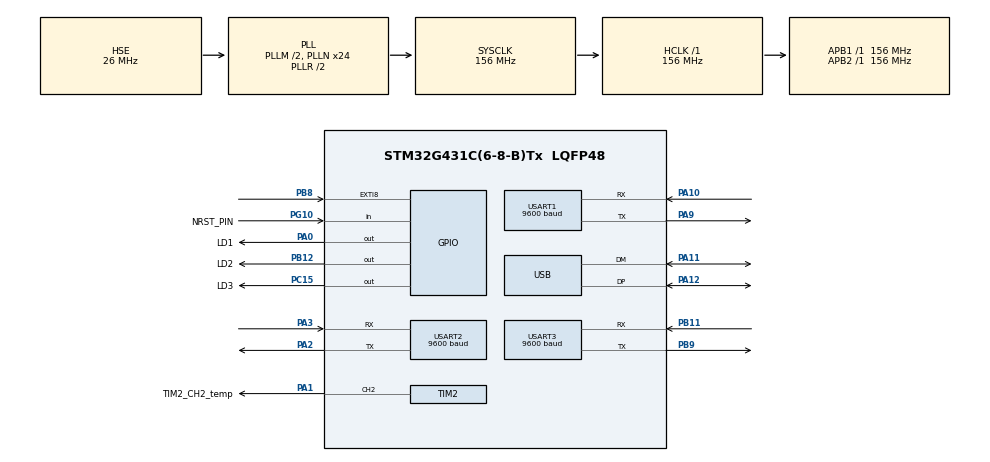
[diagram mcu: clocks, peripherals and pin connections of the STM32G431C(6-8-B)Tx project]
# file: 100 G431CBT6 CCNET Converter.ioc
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Dma.Request0=USART2_TX
Dma.Request1=USART1_TX
Dma.Request2=USART3_TX
Dma.USART1_TX.1.Direction=DMA_MEMORY_TO_PERIPH
Dma.USART1_TX.1.EventEnable=DISABLE
Dma.USART1_TX.1.Instance=DMA1_Channel2
Dma.USART1_TX.1.MemDataAlignment=DMA_MDATAALIGN_BYTE
Dma.USART1_TX.1.MemInc=DMA_MINC_ENABLE
Dma.USART1_TX.1.Mode=DMA_NORMAL
Dma.USART1_TX.1.PeriphDataAlignment=DMA_PDATAALIGN_BYTE
Dma.USART1_TX.1.PeriphInc=DMA_PINC_DISABLE
Dma.USART1_TX.1.Polarity=HAL_DMAMUX_REQ_GEN_RISING
Dma.USART1_TX.1.Priority=DMA_PRIORITY_MEDIUM
Dma.USART1_TX.1.RequestNumber=1
Dma.USART1_TX.1.SignalID=NONE
Dma.USART1_TX.1.SyncEnable=DISABLE
Dma.USART1_TX.1.SyncPolarity=HAL_DMAMUX_SYNC_NO_EVENT
Dma.USART1_TX.1.SyncRequestNumber=1
Dma.USART1_TX.1.SyncSignalID=NONE
Dma.USART2_TX.0.Direction=DMA_MEMORY_TO_PERIPH
Dma.USART2_TX.0.EventEnable=DISABLE
Dma.USART2_TX.0.Instance=DMA1_Channel1
Dma.USART2_TX.0.MemDataAlignment=DMA_MDATAALIGN_BYTE
Dma.USART2_TX.0.MemInc=DMA_MINC_ENABLE
Dma.USART2_TX.0.Mode=DMA_NORMAL
Dma.USART2_TX.0.PeriphDataAlignment=DMA_PDATAALIGN_BYTE
Dma.USART2_TX.0.PeriphInc=DMA_PINC_DISABLE
Dma.USART2_TX.0.Polarity=HAL_DMAMUX_REQ_GEN_RISING
Dma.USART2_TX.0.Priority=DMA_PRIORITY_MEDIUM
Dma.USART2_TX.0.RequestNumber=1
Dma.USART2_TX.0.SignalID=NONE
Dma.USART2_TX.0.SyncEnable=DISABLE
Dma.USART2_TX.0.SyncPolarity=HAL_DMAMUX_SYNC_NO_EVENT
Dma.USART2_TX.0.SyncRequestNumber=1
Dma.USART2_TX.0.SyncSignalID=NONE
Dma.USART3_TX.2.Direction=DMA_MEMORY_TO_PERIPH
Dma.USART3_TX.2.EventEnable=DISABLE
Dma.USART3_TX.2.Instance=DMA1_Channel3
Dma.USART3_TX.2.MemDataAlignment=DMA_MDATAALIGN_BYTE
Dma.USART3_TX.2.MemInc=DMA_MINC_ENABLE
Dma.USART3_TX.2.Mode=DMA_NORMAL
Dma.USART3_TX.2.PeriphDataAlignment=DMA_PDATAALIGN_BYTE
Dma.USART3_TX.2.PeriphInc=DMA_PINC_DISABLE
Dma.USART3_TX.2.Polarity=HAL_DMAMUX_REQ_GEN_RISING
Dma.USART3_TX.2.Priority=DMA_PRIORITY_LOW
Dma.USART3_TX.2.RequestNumber=1
Dma.USART3_TX.2.SignalID=NONE
Dma.USART3_TX.2.SyncEnable=DISABLE
Dma.USART3_TX.2.SyncPolarity=HAL_DMAMUX_SYNC_NO_EVENT
Dma.USART3_TX.2.SyncRequestNumber=1
Dma.USART3_TX.2.SyncSignalID=NONE
Mcu.Family=STM32G4
Mcu.Name=STM32G431C(6-8-B)Tx
Mcu.Package=LQFP48
NVIC.DMA1_Channel1_IRQn=true\:0\:0\:false\:false\:true\:false\:true\:true
NVIC.DMA1_Channel2_IRQn=true\:0\:0\:false\:false\:true\:false\:true\:true
NVIC.DMA1_Channel3_IRQn=true\:0\:0\:false\:false\:true\:false\:true\:true
NVIC.EXTI9_5_IRQn=true\:0\:0\:false\:false\:true\:true\:true\:true
NVIC.PriorityGroup=NVIC_PRIORITYGROUP_4
NVIC.TIM1_TRG_COM_TIM17_IRQn=true\:0\:0\:false\:false\:true\:true\:true\:true
NVIC.TIM1_UP_TIM16_IRQn=true\:0\:0\:false\:false\:true\:true\:true\:true
NVIC.USART1_IRQn=true\:0\:0\:false\:false\:true\:true\:true\:true
NVIC.USART2_IRQn=true\:0\:0\:false\:false\:true\:true\:true\:true
NVIC.USART3_IRQn=true\:0\:0\:false\:false\:true\:true\:true\:true
NVIC.USB_LP_IRQn=true\:0\:0\:false\:false\:true\:false\:true\:true
PA0.GPIO_Label=LD1
PA0.Signal=GPIO_Output
PA1.GPIO_Label=TIM2_CH2_temp
PA1.GPIO_Speed=GPIO_SPEED_FREQ_VERY_HIGH
PA1.Signal=S_TIM2_CH2
PA10.Mode=Asynchronous
PA10.Signal=USART1_RX
PA11.Mode=Device
PA11.Signal=USB_DM
PA12.Mode=Device
PA12.Signal=USB_DP
PA13.Mode=Trace_Asynchronous_SW
PA13.Signal=SYS_JTMS-SWDIO
PA14.Mode=Trace_Asynchronous_SW
PA14.Signal=SYS_JTCK-SWCLK
PA2.Mode=Asynchronous
PA2.Signal=USART2_TX
PA3.Mode=Asynchronous
PA3.Signal=USART2_RX
PA9.Mode=Asynchronous
PA9.Signal=USART1_TX
PB11.Mode=Asynchronous
PB11.Signal=USART3_RX
PB12.GPIO_Label=LD2
PB12.Signal=GPIO_Output
PB3.Mode=Trace_Asynchronous_SW
PB3.Signal=SYS_JTDO-SWO
PB8-BOOT0.GPIO_ModeDefaultEXTI=GPIO_MODE_IT_RISING_FALLING
PB8-BOOT0.Signal=GPXTI8
PB9.GPIO_ModeDefaultPP=GPIO_MODE_AF_OD
PB9.Mode=Asynchronous
PB9.Signal=USART3_TX
PC15-OSC32_OUT.GPIO_Label=LD3
PC15-OSC32_OUT.Signal=GPIO_Output
PF0-OSC_IN.Mode=HSE-External-Clock-Source
PF0-OSC_IN.Signal=RCC_OSC_IN
PG10-NRST.GPIO_Label=NRST_PIN
PG10-NRST.Signal=GPIO_Input
ProjectManager.HeapSize=0x200
ProjectManager.StackSize=0x400
ProjectManager.TargetToolchain=STM32CubeIDE
RCC.ADC12Freq_Value=156000000
RCC.AHBFreq_Value=156000000
RCC.APB1Freq_Value=156000000
RCC.APB1TimFreq_Value=156000000
RCC.APB2Freq_Value=156000000
RCC.APB2TimFreq_Value=156000000
RCC.CK48CLockSelection=RCC_USBCLKSOURCE_HSI48
RCC.CortexFreq_Value=156000000
RCC.EXTERNAL_CLOCK_VALUE=12288000
RCC.HCLKFreq_Value=156000000
RCC.HSE_VALUE=26000000
RCC.HSI48_VALUE=48000000
RCC.HSI_VALUE=16000000
RCC.LSE_VALUE=32768
RCC.PLLM=RCC_PLLM_DIV2
RCC.PLLN=24
RCC.PLLQ=RCC_PLLQ_DIV4
RCC.PLLSourceVirtual=RCC_PLLSOURCE_HSE
RCC.SYSCLKFreq_VALUE=156000000
RCC.SYSCLKSource=RCC_SYSCLKSOURCE_PLLCLK
RCC.USBFreq_Value=48000000
RCC.VCOOutputFreq_Value=312000000
SH.S_TIM2_CH2.0=TIM2_CH2,PWM Generation2 CH2
TIM17.Prescaler=15600-1
TIM2.Channel-PWM\ Generation2\ CH2=TIM_CHANNEL_2
TIM2.PeriodNoDither=6-1
TIM2.Prescaler=1-1
TIM2.PulseNoDither_2=3
USART1.BaudRate=9600
USART1.VirtualMode-Asynchronous=VM_ASYNC
USART2.BaudRate=9600
USART2.Parity=PARITY_EVEN
USART2.VirtualMode-Asynchronous=VM_ASYNC
USART2.WordLength=WORDLENGTH_9B
USART3.BaudRate=9600
USART3.TxPinLevelInvertParam=ADVFEATURE_TXINV_DISABLE
USART3.VirtualMode-Asynchronous=VM_ASYNC
USB_DEVICE.CLASS_NAME_FS=CDC
USB_DEVICE.VirtualMode=Cdc
USB_DEVICE.VirtualModeFS=Cdc_FS
VP_SYS_VS_DBSignals.Mode=DisableDeadBatterySignals
VP_TIM16_VS_ClockSourceINT.Mode=Enable_Timer
VP_TIM17_VS_ClockSourceINT.Mode=Enable_Timer
VP_USB_DEVICE_VS_USB_DEVICE_CDC_FS.Mode=CDC_FS
board=custom

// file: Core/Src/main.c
/* USER CODE BEGIN Header */
/**
  ******************************************************************************
  * @file           : main.c
  * @brief          : Main program body
  ******************************************************************************
  * @attention
  *
  * Copyright (c) 2025 STMicroelectronics.
  * All rights reserved.
  *
  * This software is licensed under terms that can be found in the LICENSE file
  * in the root directory of this software component.
  * If no LICENSE file comes with this software, it is provided AS-IS.
  *
  ******************************************************************************
  */
/* USER CODE END Header */
#include "main.h"
#include "usb_device.h"

/* USER CODE BEGIN Includes */
#include "app.h"
/* USER CODE END Includes */

TIM_HandleTypeDef htim2;
TIM_HandleTypeDef htim16;
TIM_HandleTypeDef htim17;

UART_HandleTypeDef huart1;
UART_HandleTypeDef huart2;
UART_HandleTypeDef huart3;
DMA_HandleTypeDef hdma_usart1_tx;
DMA_HandleTypeDef hdma_usart2_tx;
DMA_HandleTypeDef hdma_usart3_tx;

void SystemClock_Config(void);
static void MX_GPIO_Init(void);
static void MX_DMA_Init(void);
static void MX_USART1_UART_Init(void);
static void MX_USART2_UART_Init(void);
static void MX_USART3_UART_Init(void);
static void MX_TIM2_Init(void);
static void MX_TIM17_Init(void);
static void MX_TIM16_Init(void);

int main(void)
{

  /* MCU Configuration--------------------------------------------------------*/

  /* Reset of all peripherals, Initializes the Flash interface and the Systick. */
  HAL_Init();

  /* Configure the system clock */
  SystemClock_Config();

  /* Initialize all configured peripherals */
  MX_GPIO_Init();
  MX_DMA_Init();
  MX_USART1_UART_Init();
  MX_USART2_UART_Init();
  MX_USART3_UART_Init();
  MX_TIM2_Init();
  MX_TIM17_Init();
  MX_USB_Device_Init();
  MX_TIM16_Init();
  /* USER CODE BEGIN 2 */
  /* Initialize application */
  APP_Init();
  /* USER CODE END 2 */

  /* Infinite loop */
  while (1)
  {

    /* USER CODE BEGIN 3 */
    /* Process application */
    APP_Process();
  }
  /* USER CODE END 3 */
}

void SystemClock_Config(void)
{
  RCC_OscInitTypeDef RCC_OscInitStruct = {0};
  RCC_ClkInitTypeDef RCC_ClkInitStruct = {0};

  /** Configure the main internal regulator output voltage
  */
  HAL_PWREx_ControlVoltageScaling(PWR_REGULATOR_VOLTAGE_SCALE1_BOOST);

  /** Initializes the RCC Oscillators according to the specified parameters
  * in the RCC_OscInitTypeDef structure.
  */
  RCC_OscInitStruct.OscillatorType = RCC_OSCILLATORTYPE_HSI48|RCC_OSCILLATORTYPE_HSE;
  RCC_OscInitStruct.HSEState = RCC_HSE_BYPASS;
  RCC_OscInitStruct.HSI48State = RCC_HSI48_ON;
  RCC_OscInitStruct.PLL.PLLState = RCC_PLL_ON;
  RCC_OscInitStruct.PLL.PLLSource = RCC_PLLSOURCE_HSE;
  RCC_OscInitStruct.PLL.PLLM = RCC_PLLM_DIV2;
  RCC_OscInitStruct.PLL.PLLN = 24;
  RCC_OscInitStruct.PLL.PLLP = RCC_PLLP_DIV2;
  RCC_OscInitStruct.PLL.PLLQ = RCC_PLLQ_DIV4;
  RCC_OscInitStruct.PLL.PLLR = RCC_PLLR_DIV2;
  if (HAL_RCC_OscConfig(&RCC_OscInitStruct) != HAL_OK)
  {
    Error_Handler();
  }

  /** Initializes the CPU, AHB and APB buses clocks
  */
  RCC_ClkInitStruct.ClockType = RCC_CLOCKTYPE_HCLK|RCC_CLOCKTYPE_SYSCLK
                              |RCC_CLOCKTYPE_PCLK1|RCC_CLOCKTYPE_PCLK2;
  RCC_ClkInitStruct.SYSCLKSource = RCC_SYSCLKSOURCE_PLLCLK;
  RCC_ClkInitStruct.AHBCLKDivider = RCC_SYSCLK_DIV1;
  RCC_ClkInitStruct.APB1CLKDivider = RCC_HCLK_DIV1;
  RCC_ClkInitStruct.APB2CLKDivider = RCC_HCLK_DIV1;

  if (HAL_RCC_ClockConfig(&RCC_ClkInitStruct, FLASH_LATENCY_4) != HAL_OK)
  {
    Error_Handler();
  }
}

static void MX_TIM2_Init(void)
{

  TIM_MasterConfigTypeDef sMasterConfig = {0};
  TIM_OC_InitTypeDef sConfigOC = {0};

  htim2.Instance = TIM2;
  htim2.Init.Prescaler = 1-1;
  htim2.Init.CounterMode = TIM_COUNTERMODE_UP;
  htim2.Init.Period = 5;
  htim2.Init.ClockDivision = TIM_CLOCKDIVISION_DIV1;
  htim2.Init.AutoReloadPreload = TIM_AUTORELOAD_PRELOAD_DISABLE;
  if (HAL_TIM_PWM_Init(&htim2) != HAL_OK)
  {
    Error_Handler();
  }
  sMasterConfig.MasterOutputTrigger = TIM_TRGO_RESET;
  sMasterConfig.MasterSlaveMode = TIM_MASTERSLAVEMODE_DISABLE;
  if (HAL_TIMEx_MasterConfigSynchronization(&htim2, &sMasterConfig) != HAL_OK)
  {
    Error_Handler();
  }
  sConfigOC.OCMode = TIM_OCMODE_PWM1;
  sConfigOC.Pulse = 3;
  sConfigOC.OCPolarity = TIM_OCPOLARITY_HIGH;
  sConfigOC.OCFastMode = TIM_OCFAST_DISABLE;
  if (HAL_TIM_PWM_ConfigChannel(&htim2, &sConfigOC, TIM_CHANNEL_2) != HAL_OK)
  {
    Error_Handler();
  }
  HAL_TIM_MspPostInit(&htim2);

}

static void MX_TIM16_Init(void)
{

  htim16.Instance = TIM16;
  htim16.Init.Prescaler = 0;
  htim16.Init.CounterMode = TIM_COUNTERMODE_UP;
  htim16.Init.Period = 65535;
  htim16.Init.ClockDivision = TIM_CLOCKDIVISION_DIV1;
  htim16.Init.RepetitionCounter = 0;
  htim16.Init.AutoReloadPreload = TIM_AUTORELOAD_PRELOAD_DISABLE;
  if (HAL_TIM_Base_Init(&htim16) != HAL_OK)
  {
    Error_Handler();
  }

}

static void MX_TIM17_Init(void)
{

  htim17.Instance = TIM17;
  htim17.Init.Prescaler = 15600-1;
  htim17.Init.CounterMode = TIM_COUNTERMODE_UP;
  htim17.Init.Period = 65535;
  htim17.Init.ClockDivision = TIM_CLOCKDIVISION_DIV1;
  htim17.Init.RepetitionCounter = 0;
  htim17.Init.AutoReloadPreload = TIM_AUTORELOAD_PRELOAD_DISABLE;
  if (HAL_TIM_Base_Init(&htim17) != HAL_OK)
  {
    Error_Handler();
  }

}

static void MX_USART1_UART_Init(void)
{

  huart1.Instance = USART1;
  huart1.Init.BaudRate = 9600;
  huart1.Init.WordLength = UART_WORDLENGTH_8B;
  huart1.Init.StopBits = UART_STOPBITS_1;
  huart1.Init.Parity = UART_PARITY_NONE;
  huart1.Init.Mode = UART_MODE_TX_RX;
  huart1.Init.HwFlowCtl = UART_HWCONTROL_NONE;
  huart1.Init.OverSampling = UART_OVERSAMPLING_16;
  huart1.Init.OneBitSampling = UART_ONE_BIT_SAMPLE_DISABLE;
  huart1.Init.ClockPrescaler = UART_PRESCALER_DIV1;
  huart1.AdvancedInit.AdvFeatureInit = UART_ADVFEATURE_NO_INIT;
  if (HAL_UART_Init(&huart1) != HAL_OK)
  {
    Error_Handler();
  }
  if (HAL_UARTEx_SetTxFifoThreshold(&huart1, UART_TXFIFO_THRESHOLD_1_8) != HAL_OK)
  {
    Error_Handler();
  }
  if (HAL_UARTEx_SetRxFifoThreshold(&huart1, UART_RXFIFO_THRESHOLD_1_8) != HAL_OK)
  {
    Error_Handler();
  }
  if (HAL_UARTEx_DisableFifoMode(&huart1) != HAL_OK)
  {
    Error_Handler();
  }

}

static void MX_USART2_UART_Init(void)
{

  huart2.Instance = USART2;
  huart2.Init.BaudRate = 9600;
  huart2.Init.WordLength = UART_WORDLENGTH_9B;
  huart2.Init.StopBits = UART_STOPBITS_1;
  huart2.Init.Parity = UART_PARITY_EVEN;
  huart2.Init.Mode = UART_MODE_TX_RX;
  huart2.Init.HwFlowCtl = UART_HWCONTROL_NONE;
  huart2.Init.OverSampling = UART_OVERSAMPLING_16;
  huart2.Init.OneBitSampling = UART_ONE_BIT_SAMPLE_DISABLE;
  huart2.Init.ClockPrescaler = UART_PRESCALER_DIV1;
  huart2.AdvancedInit.AdvFeatureInit = UART_ADVFEATURE_NO_INIT;
  if (HAL_UART_Init(&huart2) != HAL_OK)
  {
    Error_Handler();
  }
  if (HAL_UARTEx_SetTxFifoThreshold(&huart2, UART_TXFIFO_THRESHOLD_1_8) != HAL_OK)
  {
    Error_Handler();
  }
  if (HAL_UARTEx_SetRxFifoThreshold(&huart2, UART_RXFIFO_THRESHOLD_1_8) != HAL_OK)
  {
    Error_Handler();
  }
  if (HAL_UARTEx_DisableFifoMode(&huart2) != HAL_OK)
  {
    Error_Handler();
  }

}

static void MX_USART3_UART_Init(void)
{

  huart3.Instance = USART3;
  huart3.Init.BaudRate = 9600;
  huart3.Init.WordLength = UART_WORDLENGTH_8B;
  huart3.Init.StopBits = UART_STOPBITS_1;
  huart3.Init.Parity = UART_PARITY_NONE;
  huart3.Init.Mode = UART_MODE_TX_RX;
  huart3.Init.HwFlowCtl = UART_HWCONTROL_NONE;
  huart3.Init.OverSampling = UART_OVERSAMPLING_16;
  huart3.Init.OneBitSampling = UART_ONE_BIT_SAMPLE_DISABLE;
  huart3.Init.ClockPrescaler = UART_PRESCALER_DIV1;
  huart3.AdvancedInit.AdvFeatureInit = UART_ADVFEATURE_NO_INIT;
  if (HAL_UART_Init(&huart3) != HAL_OK)
  {
    Error_Handler();
  }
  if (HAL_UARTEx_SetTxFifoThreshold(&huart3, UART_TXFIFO_THRESHOLD_1_8) != HAL_OK)
  {
    Error_Handler();
  }
  if (HAL_UARTEx_SetRxFifoThreshold(&huart3, UART_RXFIFO_THRESHOLD_1_8) != HAL_OK)
  {
    Error_Handler();
  }
  if (HAL_UARTEx_DisableFifoMode(&huart3) != HAL_OK)
  {
    Error_Handler();
  }

}

static void MX_DMA_Init(void)
{

  /* DMA controller clock enable */
  __HAL_RCC_DMAMUX1_CLK_ENABLE();
  __HAL_RCC_DMA1_CLK_ENABLE();

  /* DMA interrupt init */
  /* DMA1_Channel1_IRQn interrupt configuration */
  HAL_NVIC_SetPriority(DMA1_Channel1_IRQn, 0, 0);
  HAL_NVIC_EnableIRQ(DMA1_Channel1_IRQn);
  /* DMA1_Channel2_IRQn interrupt configuration */
  HAL_NVIC_SetPriority(DMA1_Channel2_IRQn, 0, 0);
  HAL_NVIC_EnableIRQ(DMA1_Channel2_IRQn);
  /* DMA1_Channel3_IRQn interrupt configuration */
  HAL_NVIC_SetPriority(DMA1_Channel3_IRQn, 0, 0);
  HAL_NVIC_EnableIRQ(DMA1_Channel3_IRQn);

}

static void MX_GPIO_Init(void)
{
  GPIO_InitTypeDef GPIO_InitStruct = {0};

  /* GPIO Ports Clock Enable */
  __HAL_RCC_GPIOC_CLK_ENABLE();
  __HAL_RCC_GPIOF_CLK_ENABLE();
  __HAL_RCC_GPIOG_CLK_ENABLE();
  __HAL_RCC_GPIOA_CLK_ENABLE();
  __HAL_RCC_GPIOB_CLK_ENABLE();

  /*Configure GPIO pin Output Level */
  HAL_GPIO_WritePin(LD3_GPIO_Port, LD3_Pin, GPIO_PIN_RESET);

  /*Configure GPIO pin Output Level */
  HAL_GPIO_WritePin(LD1_GPIO_Port, LD1_Pin, GPIO_PIN_RESET);

  /*Configure GPIO pin Output Level */
  HAL_GPIO_WritePin(LD2_GPIO_Port, LD2_Pin, GPIO_PIN_RESET);

  /*Configure GPIO pin : LD3_Pin */
  GPIO_InitStruct.Pin = LD3_Pin;
  GPIO_InitStruct.Mode = GPIO_MODE_OUTPUT_PP;
  GPIO_InitStruct.Pull = GPIO_NOPULL;
  GPIO_InitStruct.Speed = GPIO_SPEED_FREQ_LOW;
  HAL_GPIO_Init(LD3_GPIO_Port, &GPIO_InitStruct);

  /*Configure GPIO pin : NRST_PIN_Pin */
  GPIO_InitStruct.Pin = NRST_PIN_Pin;
  GPIO_InitStruct.Mode = GPIO_MODE_INPUT;
  GPIO_InitStruct.Pull = GPIO_NOPULL;
  HAL_GPIO_Init(NRST_PIN_GPIO_Port, &GPIO_InitStruct);

  /*Configure GPIO pin : LD1_Pin */
  GPIO_InitStruct.Pin = LD1_Pin;
  GPIO_InitStruct.Mode = GPIO_MODE_OUTPUT_PP;
  GPIO_InitStruct.Pull = GPIO_NOPULL;
  GPIO_InitStruct.Speed = GPIO_SPEED_FREQ_LOW;
  HAL_GPIO_Init(LD1_GPIO_Port, &GPIO_InitStruct);

  /*Configure GPIO pin : LD2_Pin */
  GPIO_InitStruct.Pin = LD2_Pin;
  GPIO_InitStruct.Mode = GPIO_MODE_OUTPUT_PP;
  GPIO_InitStruct.Pull = GPIO_NOPULL;
  GPIO_InitStruct.Speed = GPIO_SPEED_FREQ_LOW;
  HAL_GPIO_Init(LD2_GPIO_Port, &GPIO_InitStruct);

  /*Configure GPIO pin : PB8 */
  GPIO_InitStruct.Pin = GPIO_PIN_8;
  GPIO_InitStruct.Mode = GPIO_MODE_IT_RISING_FALLING;
  GPIO_InitStruct.Pull = GPIO_NOPULL;
  HAL_GPIO_Init(GPIOB, &GPIO_InitStruct);

  /* EXTI interrupt init*/
  HAL_NVIC_SetPriority(EXTI9_5_IRQn, 0, 0);
  HAL_NVIC_EnableIRQ(EXTI9_5_IRQn);

}

/* USER CODE BEGIN 4 */

/**
  * @brief  EXTI line detection callbacks
  * @param  GPIO_Pin: Specifies the pins connected EXTI line
  * @retval None
  */
void HAL_GPIO_EXTI_Callback(uint16_t GPIO_Pin)
{
    if (GPIO_Pin == GPIO_PIN_8)  /* PB8 config/reset button interrupt */
    {
        /* Config/Reset button interrupt - handle both rising and falling edge */
        extern void BTN_ConfigResetButtonInterrupt(void);
        BTN_ConfigResetButtonInterrupt();
    }
}

/**
  * @brief  Rx Transfer completed callback
  * @param  huart: UART handle
  * @retval None
  */
void HAL_UART_RxCpltCallback(UART_HandleTypeDef *huart)
{
    extern void UART_RxCpltCallback(UART_HandleTypeDef *huart);
    UART_RxCpltCallback(huart);
}

/* USER CODE END 4 */

void Error_Handler(void)
{
  __disable_irq();
  while (1)
  {
  }
}
